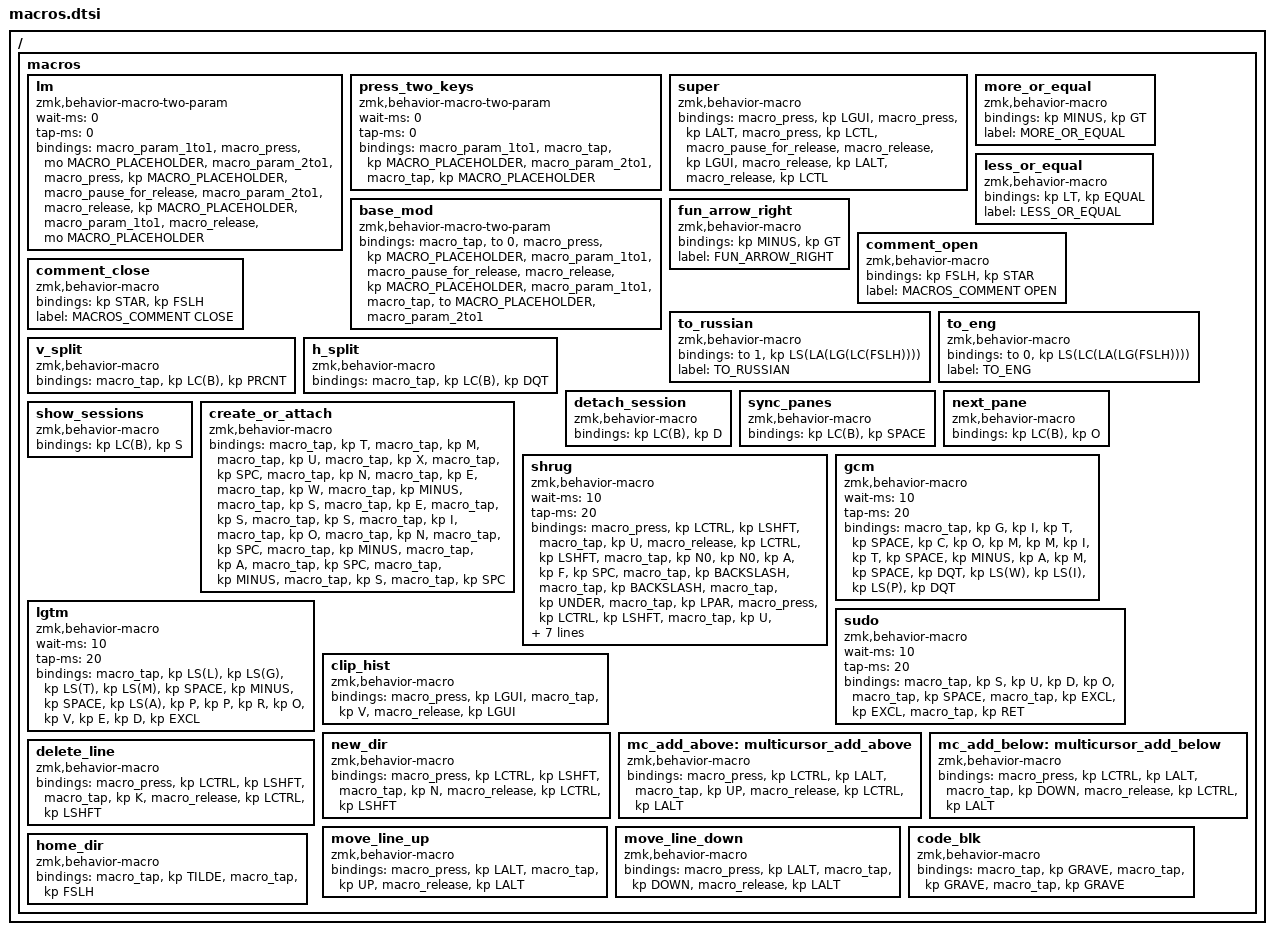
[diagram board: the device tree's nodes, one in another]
/ {
    macros {
        /**
         * Temporarily switches to a layer (`&mo`) while a modifier is held.
         * Analogous to QMK's `LM()`, using a parameterized macro.
         *
         * Params:
         *  1. Layer to switch to
         *  2. Modifier to press while layer is active
         *
         * Example:
         *  `&lm NUM_LAYER LSHIFT`
         */
        lm: lm {
            compatible = "zmk,behavior-macro-two-param";
            wait-ms = <0>;
            tap-ms = <0>;
            #binding-cells = <2>;
            bindings =
                <&macro_param_1to1>,
                <&macro_press>,
                <&mo MACRO_PLACEHOLDER &macro_param_2to1>,
                <&macro_press>,
                <&kp MACRO_PLACEHOLDER>,
                <&macro_pause_for_release>,
                <&macro_param_2to1>,
                <&macro_release>,
                <&kp MACRO_PLACEHOLDER &macro_param_1to1>,
                <&macro_release>,
                <&mo MACRO_PLACEHOLDER>;
        };

        press_two_keys: press_two_keys {
            compatible = "zmk,behavior-macro-two-param";
            wait-ms = <0>;
            tap-ms = <0>;
            #binding-cells = <2>;
            bindings =
                <&macro_param_1to1>,
                <&macro_tap>,
                <&kp MACRO_PLACEHOLDER &macro_param_2to1>,
                <&macro_tap>,
                <&kp MACRO_PLACEHOLDER>;
        };

        super: super {
            compatible = "zmk,behavior-macro";
            #binding-cells = <0>;
            bindings
                = <&macro_press &kp LGUI>
                , <&macro_press &kp LALT>
                , <&macro_press &kp LCTL>
                , <&macro_pause_for_release>
                , <&macro_release &kp LGUI>
                , <&macro_release &kp LALT>
                , <&macro_release &kp LCTL>
                ;
        };

        /**
         * go to first layer with pressed modifier, then go to another layer
         * use &base_mod MODIFIER LAYER-TO-GO-BACK
         */
        base_mod: base_mod {
            compatible = "zmk,behavior-macro-two-param";
            #binding-cells = <2>;
            bindings
                = <&macro_tap &to 0>
                , <&macro_press &kp MACRO_PLACEHOLDER &macro_param_1to1>
                , <&macro_pause_for_release>
                , <&macro_release &kp MACRO_PLACEHOLDER &macro_param_1to1>
                , <&macro_tap &to MACRO_PLACEHOLDER &macro_param_2to1>
                ;
        };

        more_or_equal: more_or_equal {
            compatible = "zmk,behavior-macro";
            #binding-cells = <0>;
            bindings = <&kp MINUS &kp GT>;
            label = "MORE_OR_EQUAL";
        };

        less_or_equal: less_or_equal {
            compatible = "zmk,behavior-macro";
            #binding-cells = <0>;
            bindings = <&kp LT &kp EQUAL>;
            label = "LESS_OR_EQUAL";
        };

        fun_arrow_right: fun_arrow_right {
            compatible = "zmk,behavior-macro";
            #binding-cells = <0>;
            bindings = <&kp MINUS &kp GT>;
            label = "FUN_ARROW_RIGHT";
        };

        comment_open: comment_open {
            compatible = "zmk,behavior-macro";
            #binding-cells = <0>;
            bindings = <&kp FSLH &kp STAR>;
            label = "MACROS_COMMENT OPEN";
        };

        comment_close: comment_close {
            compatible = "zmk,behavior-macro";
            #binding-cells = <0>;
            bindings = <&kp STAR &kp FSLH>;
            label = "MACROS_COMMENT CLOSE";
        };

        to_russian: to_russian {
            compatible = "zmk,behavior-macro";
            #binding-cells = <0>;
            bindings = <&to 1 &kp LS(LA(LG(LC(FSLH))))>;
            label = "TO_RUSSIAN";
        };

        to_eng: to_eng {
            compatible = "zmk,behavior-macro";
            #binding-cells = <0>;
            bindings = <&to 0 &kp LS(LC(LA(LG(FSLH))))>;
            label = "TO_ENG";
        };

        v_split: v_split {
            compatible = "zmk,behavior-macro";
            #binding-cells = <0>;
            bindings = <&macro_tap &kp LC(B) &kp PRCNT>;
        };

        h_split: h_split {
            compatible = "zmk,behavior-macro";
            #binding-cells = <0>;
            bindings = <&macro_tap &kp LC(B) &kp DQT>;
        };

        detach_session: detach_session {
            compatible = "zmk,behavior-macro";
            #binding-cells = <0>;
            bindings = <&kp LC(B) &kp D>;
        };

        sync_panes: sync_panes {
            compatible = "zmk,behavior-macro";
            #binding-cells = <0>;
            bindings = <&kp LC(B) &kp SPACE>;
        };

        next_pane: next_pane {
            compatible = "zmk,behavior-macro";
            #binding-cells = <0>;
            bindings = <&kp LC(B) &kp O>;
        };

        show_sessions: show_sessions {
            compatible = "zmk,behavior-macro";
            #binding-cells = <0>;
            bindings = <&kp LC(B) &kp S>;
        };

        create_or_attach: create_or_attach {
            compatible = "zmk,behavior-macro";
            #binding-cells = <0>;
            bindings
                = <&macro_tap &kp T>
                , <&macro_tap &kp M>
                , <&macro_tap &kp U>
                , <&macro_tap &kp X>
                , <&macro_tap &kp SPC>
                , <&macro_tap &kp N>
                , <&macro_tap &kp E>
                , <&macro_tap &kp W>
                , <&macro_tap &kp MINUS>
                , <&macro_tap &kp S>
                , <&macro_tap &kp E>
                , <&macro_tap &kp S>
                , <&macro_tap &kp S>
                , <&macro_tap &kp I>
                , <&macro_tap &kp O>
                , <&macro_tap &kp N>
                , <&macro_tap &kp SPC>
                , <&macro_tap &kp MINUS>
                , <&macro_tap &kp A>
                , <&macro_tap &kp SPC>
                , <&macro_tap &kp MINUS>
                , <&macro_tap &kp S>
                , <&macro_tap &kp SPC>
            ;
        };

        shrug: shrug { // shrug emoji ¯\_(ツ)_/¯
            compatible = "zmk,behavior-macro";
            #binding-cells = <0>;
            wait-ms = <10>;
            tap-ms = <20>;
            bindings
                // ¯ (Macros)
                = <&macro_press &kp LCTRL &kp LSHFT>
                , <&macro_tap &kp U>
                , <&macro_release &kp LCTRL &kp LSHFT>
                , <&macro_tap &kp N0 &kp N0 &kp A &kp F &kp SPC>
                // \
                , <&macro_tap &kp BACKSLASH>
                , <&macro_tap &kp BACKSLASH>
                // _
                , <&macro_tap &kp UNDER>
                // (
                , <&macro_tap &kp LPAR>
                // ツ (Katakana Letter Tu)
                , <&macro_press &kp LCTRL &kp LSHFT>
                , <&macro_tap &kp U>
                , <&macro_release &kp LCTRL &kp LSHFT>
                , <&macro_tap &kp N3 &kp N0 &kp C &kp N4 &kp SPC>
                // )
                , <&macro_tap &kp RPAR>
                // _
                , <&macro_tap &kp UNDER>
                // /
                , <&macro_tap &kp FSLH>
                // ¯ (Macron)
                , <&macro_press &kp LCTRL &kp LSHFT>
                , <&macro_tap &kp U>
                , <&macro_release &kp LCTRL &kp LSHFT>
                , <&macro_tap &kp N0 &kp N0 &kp A &kp F &kp SPC>
                ;
        };

        gcm: gcm { // git commit WIP
            compatible = "zmk,behavior-macro";
            #binding-cells = <0>;
            wait-ms = <10>;
            tap-ms = <20>;
            bindings = <
                &macro_tap &kp G &kp I &kp T &kp SPACE
                &kp C &kp O &kp M &kp M &kp I &kp T &kp SPACE
                &kp MINUS &kp A &kp M &kp SPACE
                &kp DQT &kp LS(W) &kp LS(I) &kp LS(P) &kp DQT
            >;
        };

        lgtm: lgtm { // LGTM Approval
            compatible = "zmk,behavior-macro";
            #binding-cells = <0>;
            wait-ms = <10>;
            tap-ms = <20>;
            bindings = <
                &macro_tap
                &kp LS(L) &kp LS(G) &kp LS(T) &kp LS(M)
                &kp SPACE &kp MINUS &kp SPACE
                &kp LS(A) &kp P &kp P &kp R &kp O &kp V &kp E &kp D &kp EXCL
            >;
        };

        sudo: sudo { // SUDO_BANG_BANG
            compatible = "zmk,behavior-macro";
            #binding-cells = <0>;
            wait-ms = <10>;
            tap-ms = <20>;
            bindings
                = <&macro_tap &kp S &kp U &kp D &kp O>  // "sudo"
                , <&macro_tap &kp SPACE>                // space
                , <&macro_tap &kp EXCL &kp EXCL>        // "!!"
                , <&macro_tap &kp RET>                  // Enter key
                ;
        };
        
        clip_hist: clip_hist { // CLIPBOARD_HISTORY
            compatible = "zmk,behavior-macro";
            #binding-cells = <0>;
            bindings 
                = <&macro_press &kp LGUI>
                , <&macro_tap &kp V>
                , <&macro_release &kp LGUI>
                ;
        };
        
        new_dir: new_dir {
            compatible = "zmk,behavior-macro";
            #binding-cells = <0>;
            bindings
                = <&macro_press &kp LCTRL &kp LSHFT>
                , <&macro_tap &kp N>
                , <&macro_release &kp LCTRL &kp LSHFT>
                ;
        };

        mc_add_above: multicursor_add_above {
            compatible = "zmk,behavior-macro";
            #binding-cells = <0>;
            bindings
                = <&macro_press &kp LCTRL &kp LALT>
                , <&macro_tap &kp UP>
                , <&macro_release &kp LCTRL &kp LALT>
                ;
        };

        mc_add_below: multicursor_add_below {
            compatible = "zmk,behavior-macro";
            #binding-cells = <0>;
            bindings
                = <&macro_press &kp LCTRL &kp LALT>
                , <&macro_tap &kp DOWN>
                , <&macro_release &kp LCTRL &kp LALT>
                ;
        };

        delete_line: delete_line {
            compatible = "zmk,behavior-macro";
            #binding-cells = <0>;
            bindings
                = <&macro_press &kp LCTRL &kp LSHFT>
                , <&macro_tap &kp K>
                , <&macro_release &kp LCTRL &kp LSHFT>
                ;
        };

        move_line_up: move_line_up {
            compatible = "zmk,behavior-macro";
            #binding-cells = <0>;
            bindings
                = <&macro_press &kp LALT>
                , <&macro_tap &kp UP>
                , <&macro_release &kp LALT>
                ;
        };

        move_line_down: move_line_down {
            compatible = "zmk,behavior-macro";
            #binding-cells = <0>;
            bindings
                = <&macro_press &kp LALT>
                , <&macro_tap &kp DOWN>
                , <&macro_release &kp LALT>
                ;
        };

        code_blk: code_blk {
            compatible = "zmk,behavior-macro";
            #binding-cells = <0>;
            bindings
                = <&macro_tap &kp GRAVE>
                , <&macro_tap &kp GRAVE>
                , <&macro_tap &kp GRAVE>
                ;
        };
        
        home_dir: home_dir {
            compatible = "zmk,behavior-macro";
            #binding-cells = <0>;
            bindings
                = <&macro_tap &kp TILDE>
                , <&macro_tap &kp FSLH>
                ;
        };
    };
};
